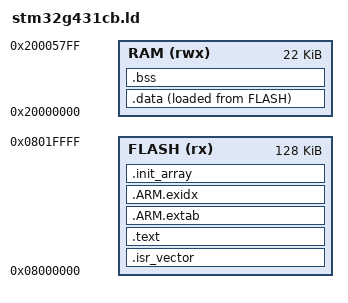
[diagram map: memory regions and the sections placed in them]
ENTRY(Reset_Handler)
MEMORY {
  FLASH (rx) : ORIGIN = 0x08000000, LENGTH = 128K
  RAM (rwx)  : ORIGIN = 0x20000000, LENGTH = 22K
}
_estack = ORIGIN(RAM) + LENGTH(RAM);
SECTIONS {
  .isr_vector : { KEEP(*(.isr_vector)) } > FLASH
  .text : { *(.text*) *(.rodata*) . = ALIGN(4); } > FLASH
  .ARM.extab : { *(.ARM.extab*) } > FLASH
  .ARM.exidx : { *(.ARM.exidx*) } > FLASH
  .init_array : {
    . = ALIGN(4); __init_array_start = .;
    KEEP(*(SORT_BY_INIT_PRIORITY(.init_array.*))) KEEP(*(.init_array))
    __init_array_end = .;
  } > FLASH
  .data : {
    . = ALIGN(4); _sdata = .; *(.data*) . = ALIGN(4); _edata = .;
  } > RAM AT > FLASH
  _sidata = LOADADDR(.data);
  .bss (NOLOAD) : {
    . = ALIGN(4); _sbss = .; *(.bss*) *(COMMON) . = ALIGN(4); _ebss = .;
  } > RAM
  /DISCARD/ : { *(.comment) *(.note*) }
  ASSERT(_ebss <= _estack - 2048, "RAM overflow: reserve 2 KiB stack")
}
